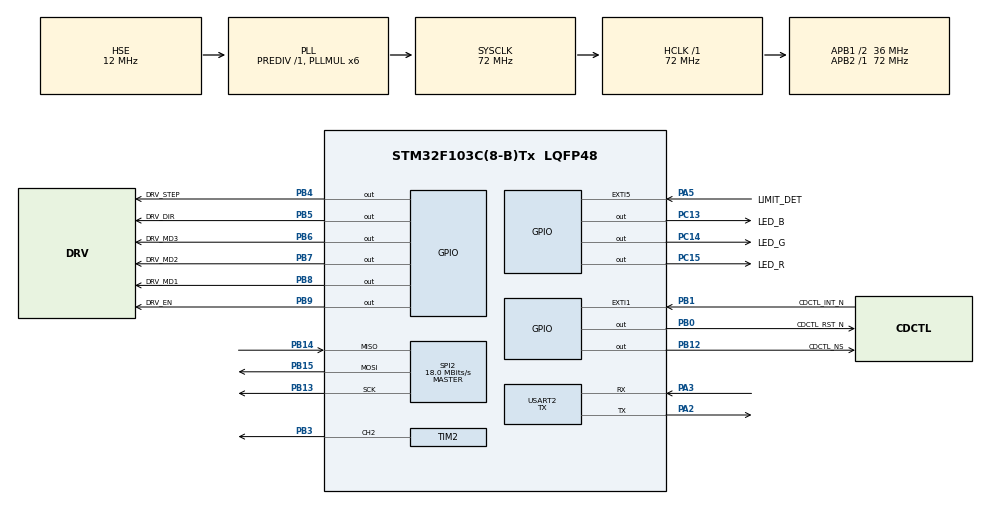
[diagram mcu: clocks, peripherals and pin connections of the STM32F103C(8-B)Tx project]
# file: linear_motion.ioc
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Dma.Request0=SPI2_RX
Dma.Request1=SPI2_TX
Dma.Request2=USART2_TX
Dma.SPI2_RX.0.Direction=DMA_PERIPH_TO_MEMORY
Dma.SPI2_RX.0.Instance=DMA1_Channel4
Dma.SPI2_RX.0.MemDataAlignment=DMA_MDATAALIGN_BYTE
Dma.SPI2_RX.0.MemInc=DMA_MINC_ENABLE
Dma.SPI2_RX.0.Mode=DMA_NORMAL
Dma.SPI2_RX.0.PeriphDataAlignment=DMA_PDATAALIGN_BYTE
Dma.SPI2_RX.0.PeriphInc=DMA_PINC_DISABLE
Dma.SPI2_RX.0.Priority=DMA_PRIORITY_LOW
Dma.SPI2_TX.1.Direction=DMA_MEMORY_TO_PERIPH
Dma.SPI2_TX.1.Instance=DMA1_Channel5
Dma.SPI2_TX.1.MemDataAlignment=DMA_MDATAALIGN_BYTE
Dma.SPI2_TX.1.MemInc=DMA_MINC_ENABLE
Dma.SPI2_TX.1.Mode=DMA_NORMAL
Dma.SPI2_TX.1.PeriphDataAlignment=DMA_PDATAALIGN_BYTE
Dma.SPI2_TX.1.PeriphInc=DMA_PINC_DISABLE
Dma.SPI2_TX.1.Priority=DMA_PRIORITY_LOW
Dma.USART2_TX.2.Direction=DMA_MEMORY_TO_PERIPH
Dma.USART2_TX.2.Instance=DMA1_Channel7
Dma.USART2_TX.2.MemDataAlignment=DMA_MDATAALIGN_BYTE
Dma.USART2_TX.2.MemInc=DMA_MINC_ENABLE
Dma.USART2_TX.2.Mode=DMA_NORMAL
Dma.USART2_TX.2.PeriphDataAlignment=DMA_PDATAALIGN_BYTE
Dma.USART2_TX.2.PeriphInc=DMA_PINC_DISABLE
Dma.USART2_TX.2.Priority=DMA_PRIORITY_LOW
Mcu.Family=STM32F1
Mcu.Name=STM32F103C(8-B)Tx
Mcu.Package=LQFP48
NVIC.DMA1_Channel4_IRQn=true\:1\:1\:true\:false\:true\:false\:true
NVIC.DMA1_Channel5_IRQn=true\:1\:0\:true\:false\:true\:false\:true
NVIC.DMA1_Channel7_IRQn=true\:1\:1\:true\:false\:true\:false\:true
NVIC.EXTI1_IRQn=true\:1\:0\:true\:false\:true\:true\:true
NVIC.EXTI9_5_IRQn=true\:1\:0\:true\:false\:true\:true\:true
NVIC.PriorityGroup=NVIC_PRIORITYGROUP_2
NVIC.TIM1_UP_IRQn=true\:1\:0\:true\:false\:true\:true\:true
PA13.Mode=Serial_Wire
PA13.Signal=SYS_JTMS-SWDIO
PA14.Mode=Serial_Wire
PA14.Signal=SYS_JTCK-SWCLK
PA2.Mode=Asynchronous
PA2.Signal=USART2_TX
PA3.Mode=Asynchronous
PA3.Signal=USART2_RX
PA5.GPIO_Label=LIMIT_DET
PA5.GPIO_ModeDefaultEXTI=GPIO_MODE_IT_FALLING
PA5.Signal=GPXTI5
PB0.GPIO_Label=CDCTL_RST_N
PB0.PinState=GPIO_PIN_SET
PB0.Signal=GPIO_Output
PB1.GPIO_Label=CDCTL_INT_N
PB1.GPIO_ModeDefaultEXTI=GPIO_MODE_IT_FALLING
PB1.Signal=GPXTI1
PB12.GPIO_Label=CDCTL_NS
PB12.GPIO_Speed=GPIO_SPEED_FREQ_HIGH
PB12.PinState=GPIO_PIN_SET
PB12.Signal=GPIO_Output
PB13.Mode=Full_Duplex_Master
PB13.Signal=SPI2_SCK
PB14.Mode=Full_Duplex_Master
PB14.Signal=SPI2_MISO
PB15.Mode=Full_Duplex_Master
PB15.Signal=SPI2_MOSI
PB3.Signal=S_TIM2_CH2
PB4.GPIO_Label=DRV_STEP
PB4.Signal=GPIO_Output
PB5.GPIO_Label=DRV_DIR
PB5.PinState=GPIO_PIN_RESET
PB5.Signal=GPIO_Output
PB6.GPIO_Label=DRV_MD3
PB6.Signal=GPIO_Output
PB7.GPIO_Label=DRV_MD2
PB7.Signal=GPIO_Output
PB8.GPIO_Label=DRV_MD1
PB8.Signal=GPIO_Output
PB9.GPIO_Label=DRV_EN
PB9.Signal=GPIO_Output
PC13-TAMPER-RTC.GPIO_Label=LED_B
PC13-TAMPER-RTC.PinState=GPIO_PIN_SET
PC13-TAMPER-RTC.Signal=GPIO_Output
PC14-OSC32_IN.GPIO_Label=LED_G
PC14-OSC32_IN.PinState=GPIO_PIN_SET
PC14-OSC32_IN.Signal=GPIO_Output
PC15-OSC32_OUT.GPIO_Label=LED_R
PC15-OSC32_OUT.PinState=GPIO_PIN_SET
PC15-OSC32_OUT.Signal=GPIO_Output
PD0-OSC_IN.Mode=HSE-External-Oscillator
PD0-OSC_IN.Signal=RCC_OSC_IN
PD1-OSC_OUT.Mode=HSE-External-Oscillator
PD1-OSC_OUT.Signal=RCC_OSC_OUT
ProjectManager.HeapSize=0x200
ProjectManager.StackSize=0x800
ProjectManager.TargetToolchain=Makefile
RCC.AHBFreq_Value=72000000
RCC.APB1CLKDivider=RCC_HCLK_DIV2
RCC.APB1Freq_Value=36000000
RCC.APB1TimFreq_Value=72000000
RCC.APB2Freq_Value=72000000
RCC.APB2TimFreq_Value=72000000
RCC.HCLKFreq_Value=72000000
RCC.HSE_VALUE=12000000
RCC.PLLMUL=RCC_PLL_MUL6
RCC.PLLSourceVirtual=RCC_PLLSOURCE_HSE
RCC.SYSCLKFreq_VALUE=72000000
RCC.SYSCLKSource=RCC_SYSCLKSOURCE_PLLCLK
RCC.USBFreq_Value=72000000
SH.S_TIM2_CH2.0=TIM2_CH2,PWM Generation2 CH2
SPI2.BaudRatePrescaler=SPI_BAUDRATEPRESCALER_2
SPI2.CalculateBaudRate=18.0 MBits/s
SPI2.Direction=SPI_DIRECTION_2LINES
SPI2.Mode=SPI_MODE_MASTER
SPI2.VirtualType=VM_MASTER
TIM1.Period=1000-1
TIM1.Prescaler=72-1
TIM2.AutoReloadPreload=TIM_AUTORELOAD_PRELOAD_ENABLE
TIM2.Channel-PWM\ Generation2\ CH2=TIM_CHANNEL_2
TIM2.Period=1000-1
TIM2.Prescaler=4-1
TIM2.Pulse-PWM\ Generation2\ CH2=100-1
USART2.Mode=MODE_TX
USART2.VirtualMode=VM_ASYNC
VP_TIM1_VS_ClockSourceINT.Mode=Internal
VP_TIM1_VS_OPM.Mode=OPM_bit
board=linear_motion

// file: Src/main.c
/* USER CODE BEGIN Header */
/**
  ******************************************************************************
  * @file           : main.c
  * @brief          : Main program body
  ******************************************************************************
  * @attention
  *
  * <h2><center>&copy; Copyright (c) 2019 STMicroelectronics.
  * All rights reserved.</center></h2>
  *
  * This software component is licensed by ST under BSD 3-Clause license,
  * the "License"; You may not use this file except in compliance with the
  * License. You may obtain a copy of the License at:
  *                        opensource.org/licenses/BSD-3-Clause
  *
  ******************************************************************************
  */
/* USER CODE END Header */

#include "main.h"

/* USER CODE BEGIN Includes */
#include "app_main.h"

/* USER CODE END Includes */

SPI_HandleTypeDef hspi2;
DMA_HandleTypeDef hdma_spi2_rx;
DMA_HandleTypeDef hdma_spi2_tx;

TIM_HandleTypeDef htim1;
TIM_HandleTypeDef htim2;

UART_HandleTypeDef huart2;
DMA_HandleTypeDef hdma_usart2_tx;

/* USER CODE BEGIN PV */
/* Private variables ---------------------------------------------------------*/

/* USER CODE END PV */

void SystemClock_Config(void);
static void MX_GPIO_Init(void);
static void MX_DMA_Init(void);
static void MX_USART2_UART_Init(void);
static void MX_SPI2_Init(void);
static void MX_TIM1_Init(void);
static void MX_TIM2_Init(void);
/* USER CODE BEGIN PFP */
/* Private function prototypes -----------------------------------------------*/

/* USER CODE END PFP */

int main(void)
{

  /* MCU Configuration--------------------------------------------------------*/

  /* Reset of all peripherals, Initializes the Flash interface and the Systick. */
  HAL_Init();

  /* Configure the system clock */
  SystemClock_Config();

  /* Initialize all configured peripherals */
  MX_GPIO_Init();
  MX_DMA_Init();
  MX_USART2_UART_Init();
  MX_SPI2_Init();
  MX_TIM1_Init();
  MX_TIM2_Init();
  /* USER CODE BEGIN 2 */
  void app_main(void);
  app_main();

  /* USER CODE END 2 */

  /* Infinite loop */
  while (1)
  {

  }
}

void SystemClock_Config(void)
{
  RCC_OscInitTypeDef RCC_OscInitStruct = {0};
  RCC_ClkInitTypeDef RCC_ClkInitStruct = {0};

  /** Initializes the CPU, AHB and APB busses clocks
  */
  RCC_OscInitStruct.OscillatorType = RCC_OSCILLATORTYPE_HSE;
  RCC_OscInitStruct.HSEState = RCC_HSE_ON;
  RCC_OscInitStruct.HSEPredivValue = RCC_HSE_PREDIV_DIV1;
  RCC_OscInitStruct.HSIState = RCC_HSI_ON;
  RCC_OscInitStruct.PLL.PLLState = RCC_PLL_ON;
  RCC_OscInitStruct.PLL.PLLSource = RCC_PLLSOURCE_HSE;
  RCC_OscInitStruct.PLL.PLLMUL = RCC_PLL_MUL6;
  if (HAL_RCC_OscConfig(&RCC_OscInitStruct) != HAL_OK)
  {
    Error_Handler();
  }
  /** Initializes the CPU, AHB and APB busses clocks
  */
  RCC_ClkInitStruct.ClockType = RCC_CLOCKTYPE_HCLK|RCC_CLOCKTYPE_SYSCLK
                              |RCC_CLOCKTYPE_PCLK1|RCC_CLOCKTYPE_PCLK2;
  RCC_ClkInitStruct.SYSCLKSource = RCC_SYSCLKSOURCE_PLLCLK;
  RCC_ClkInitStruct.AHBCLKDivider = RCC_SYSCLK_DIV1;
  RCC_ClkInitStruct.APB1CLKDivider = RCC_HCLK_DIV2;
  RCC_ClkInitStruct.APB2CLKDivider = RCC_HCLK_DIV1;

  if (HAL_RCC_ClockConfig(&RCC_ClkInitStruct, FLASH_LATENCY_2) != HAL_OK)
  {
    Error_Handler();
  }
}

static void MX_SPI2_Init(void)
{

  /* SPI2 parameter configuration*/
  hspi2.Instance = SPI2;
  hspi2.Init.Mode = SPI_MODE_MASTER;
  hspi2.Init.Direction = SPI_DIRECTION_2LINES;
  hspi2.Init.DataSize = SPI_DATASIZE_8BIT;
  hspi2.Init.CLKPolarity = SPI_POLARITY_LOW;
  hspi2.Init.CLKPhase = SPI_PHASE_1EDGE;
  hspi2.Init.NSS = SPI_NSS_SOFT;
  hspi2.Init.BaudRatePrescaler = SPI_BAUDRATEPRESCALER_2;
  hspi2.Init.FirstBit = SPI_FIRSTBIT_MSB;
  hspi2.Init.TIMode = SPI_TIMODE_DISABLE;
  hspi2.Init.CRCCalculation = SPI_CRCCALCULATION_DISABLE;
  hspi2.Init.CRCPolynomial = 10;
  if (HAL_SPI_Init(&hspi2) != HAL_OK)
  {
    Error_Handler();
  }

}

static void MX_TIM1_Init(void)
{

  TIM_ClockConfigTypeDef sClockSourceConfig = {0};
  TIM_MasterConfigTypeDef sMasterConfig = {0};

  htim1.Instance = TIM1;
  htim1.Init.Prescaler = 72-1;
  htim1.Init.CounterMode = TIM_COUNTERMODE_UP;
  htim1.Init.Period = 1000-1;
  htim1.Init.ClockDivision = TIM_CLOCKDIVISION_DIV1;
  htim1.Init.RepetitionCounter = 0;
  htim1.Init.AutoReloadPreload = TIM_AUTORELOAD_PRELOAD_DISABLE;
  if (HAL_TIM_Base_Init(&htim1) != HAL_OK)
  {
    Error_Handler();
  }
  sClockSourceConfig.ClockSource = TIM_CLOCKSOURCE_INTERNAL;
  if (HAL_TIM_ConfigClockSource(&htim1, &sClockSourceConfig) != HAL_OK)
  {
    Error_Handler();
  }
  if (HAL_TIM_OnePulse_Init(&htim1, TIM_OPMODE_SINGLE) != HAL_OK)
  {
    Error_Handler();
  }
  sMasterConfig.MasterOutputTrigger = TIM_TRGO_RESET;
  sMasterConfig.MasterSlaveMode = TIM_MASTERSLAVEMODE_DISABLE;
  if (HAL_TIMEx_MasterConfigSynchronization(&htim1, &sMasterConfig) != HAL_OK)
  {
    Error_Handler();
  }

}

static void MX_TIM2_Init(void)
{

  TIM_MasterConfigTypeDef sMasterConfig = {0};
  TIM_OC_InitTypeDef sConfigOC = {0};

  htim2.Instance = TIM2;
  htim2.Init.Prescaler = 4-1;
  htim2.Init.CounterMode = TIM_COUNTERMODE_UP;
  htim2.Init.Period = 1000-1;
  htim2.Init.ClockDivision = TIM_CLOCKDIVISION_DIV1;
  htim2.Init.AutoReloadPreload = TIM_AUTORELOAD_PRELOAD_ENABLE;
  if (HAL_TIM_PWM_Init(&htim2) != HAL_OK)
  {
    Error_Handler();
  }
  sMasterConfig.MasterOutputTrigger = TIM_TRGO_RESET;
  sMasterConfig.MasterSlaveMode = TIM_MASTERSLAVEMODE_DISABLE;
  if (HAL_TIMEx_MasterConfigSynchronization(&htim2, &sMasterConfig) != HAL_OK)
  {
    Error_Handler();
  }
  sConfigOC.OCMode = TIM_OCMODE_PWM1;
  sConfigOC.Pulse = 100-1;
  sConfigOC.OCPolarity = TIM_OCPOLARITY_HIGH;
  sConfigOC.OCFastMode = TIM_OCFAST_DISABLE;
  if (HAL_TIM_PWM_ConfigChannel(&htim2, &sConfigOC, TIM_CHANNEL_2) != HAL_OK)
  {
    Error_Handler();
  }
  HAL_TIM_MspPostInit(&htim2);

}

static void MX_USART2_UART_Init(void)
{

  huart2.Instance = USART2;
  huart2.Init.BaudRate = 115200;
  huart2.Init.WordLength = UART_WORDLENGTH_8B;
  huart2.Init.StopBits = UART_STOPBITS_1;
  huart2.Init.Parity = UART_PARITY_NONE;
  huart2.Init.Mode = UART_MODE_TX;
  huart2.Init.HwFlowCtl = UART_HWCONTROL_NONE;
  huart2.Init.OverSampling = UART_OVERSAMPLING_16;
  if (HAL_UART_Init(&huart2) != HAL_OK)
  {
    Error_Handler();
  }

}

static void MX_DMA_Init(void)
{

  /* DMA controller clock enable */
  __HAL_RCC_DMA1_CLK_ENABLE();

  /* DMA interrupt init */
  /* DMA1_Channel4_IRQn interrupt configuration */
  HAL_NVIC_SetPriority(DMA1_Channel4_IRQn, 1, 1);
  HAL_NVIC_EnableIRQ(DMA1_Channel4_IRQn);
  /* DMA1_Channel5_IRQn interrupt configuration */
  HAL_NVIC_SetPriority(DMA1_Channel5_IRQn, 1, 0);
  HAL_NVIC_EnableIRQ(DMA1_Channel5_IRQn);
  /* DMA1_Channel7_IRQn interrupt configuration */
  HAL_NVIC_SetPriority(DMA1_Channel7_IRQn, 1, 1);
  HAL_NVIC_EnableIRQ(DMA1_Channel7_IRQn);

}

static void MX_GPIO_Init(void)
{
  GPIO_InitTypeDef GPIO_InitStruct = {0};

  /* GPIO Ports Clock Enable */
  __HAL_RCC_GPIOC_CLK_ENABLE();
  __HAL_RCC_GPIOD_CLK_ENABLE();
  __HAL_RCC_GPIOA_CLK_ENABLE();
  __HAL_RCC_GPIOB_CLK_ENABLE();

  /*Configure GPIO pin Output Level */
  HAL_GPIO_WritePin(GPIOC, LED_B_Pin|LED_G_Pin|LED_R_Pin, GPIO_PIN_SET);

  /*Configure GPIO pin Output Level */
  HAL_GPIO_WritePin(GPIOB, CDCTL_RST_N_Pin|CDCTL_NS_Pin, GPIO_PIN_SET);

  /*Configure GPIO pin Output Level */
  HAL_GPIO_WritePin(GPIOB, DRV_STEP_Pin|DRV_DIR_Pin|DRV_MD3_Pin|DRV_MD2_Pin
                          |DRV_MD1_Pin|DRV_EN_Pin, GPIO_PIN_RESET);

  /*Configure GPIO pins : LED_B_Pin LED_G_Pin LED_R_Pin */
  GPIO_InitStruct.Pin = LED_B_Pin|LED_G_Pin|LED_R_Pin;
  GPIO_InitStruct.Mode = GPIO_MODE_OUTPUT_PP;
  GPIO_InitStruct.Pull = GPIO_NOPULL;
  GPIO_InitStruct.Speed = GPIO_SPEED_FREQ_LOW;
  HAL_GPIO_Init(GPIOC, &GPIO_InitStruct);

  /*Configure GPIO pin : LIMIT_DET_Pin */
  GPIO_InitStruct.Pin = LIMIT_DET_Pin;
  GPIO_InitStruct.Mode = GPIO_MODE_IT_FALLING;
  GPIO_InitStruct.Pull = GPIO_NOPULL;
  HAL_GPIO_Init(LIMIT_DET_GPIO_Port, &GPIO_InitStruct);

  /*Configure GPIO pins : CDCTL_RST_N_Pin DRV_STEP_Pin DRV_DIR_Pin DRV_MD3_Pin
                           DRV_MD2_Pin DRV_MD1_Pin DRV_EN_Pin */
  GPIO_InitStruct.Pin = CDCTL_RST_N_Pin|DRV_STEP_Pin|DRV_DIR_Pin|DRV_MD3_Pin
                          |DRV_MD2_Pin|DRV_MD1_Pin|DRV_EN_Pin;
  GPIO_InitStruct.Mode = GPIO_MODE_OUTPUT_PP;
  GPIO_InitStruct.Pull = GPIO_NOPULL;
  GPIO_InitStruct.Speed = GPIO_SPEED_FREQ_LOW;
  HAL_GPIO_Init(GPIOB, &GPIO_InitStruct);

  /*Configure GPIO pin : CDCTL_INT_N_Pin */
  GPIO_InitStruct.Pin = CDCTL_INT_N_Pin;
  GPIO_InitStruct.Mode = GPIO_MODE_IT_FALLING;
  GPIO_InitStruct.Pull = GPIO_NOPULL;
  HAL_GPIO_Init(CDCTL_INT_N_GPIO_Port, &GPIO_InitStruct);

  /*Configure GPIO pin : CDCTL_NS_Pin */
  GPIO_InitStruct.Pin = CDCTL_NS_Pin;
  GPIO_InitStruct.Mode = GPIO_MODE_OUTPUT_PP;
  GPIO_InitStruct.Pull = GPIO_NOPULL;
  GPIO_InitStruct.Speed = GPIO_SPEED_FREQ_HIGH;
  HAL_GPIO_Init(CDCTL_NS_GPIO_Port, &GPIO_InitStruct);

  /* EXTI interrupt init*/
  HAL_NVIC_SetPriority(EXTI1_IRQn, 1, 0);
  HAL_NVIC_EnableIRQ(EXTI1_IRQn);

  HAL_NVIC_SetPriority(EXTI9_5_IRQn, 1, 0);
  HAL_NVIC_EnableIRQ(EXTI9_5_IRQn);

}

void Error_Handler(void)
{
  while(1)
  {
  }
}

/************************ (C) COPYRIGHT STMicroelectronics *****END OF FILE****/
